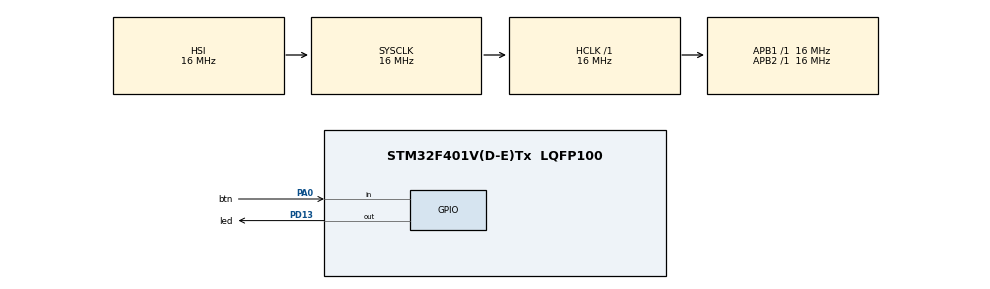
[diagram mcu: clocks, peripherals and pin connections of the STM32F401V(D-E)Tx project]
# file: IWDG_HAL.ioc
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IWDG.Prescaler=IWDG_PRESCALER_256
IWDG.Reload=625
Mcu.Family=STM32F4
Mcu.Name=STM32F401V(D-E)Tx
Mcu.Package=LQFP100
NVIC.PriorityGroup=NVIC_PRIORITYGROUP_4
PA0-WKUP.GPIO_Label=btn
PA0-WKUP.GPIO_PuPd=GPIO_PULLDOWN
PA0-WKUP.Signal=GPIO_Input
PD13.GPIO_Label=led
PD13.Signal=GPIO_Output
PH0\ -\ OSC_IN.Mode=HSE-External-Oscillator
PH0\ -\ OSC_IN.Signal=RCC_OSC_IN
PH1\ -\ OSC_OUT.Mode=HSE-External-Oscillator
PH1\ -\ OSC_OUT.Signal=RCC_OSC_OUT
ProjectManager.HeapSize=0x200
ProjectManager.StackSize=0x400
ProjectManager.TargetToolchain=STM32CubeIDE
RCC.AHBFreq_Value=16000000
RCC.APB1Freq_Value=16000000
RCC.APB2Freq_Value=16000000
RCC.CortexFreq_Value=16000000
RCC.HSE_VALUE=25000000
RCC.HSI_VALUE=16000000
RCC.LSE_VALUE=32768
RCC.SYSCLKFreq_VALUE=16000000
RCC.VCOOutputFreq_Value=192000000
VP_IWDG_VS_IWDG.Mode=IWDG_Activate
board=custom

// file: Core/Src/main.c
/* USER CODE BEGIN Header */
/**
  ******************************************************************************
  * @file           : main.c
  * @brief          : Investigate IWDG
  ******************************************************************************
  * @attention
  *
  * Copyright (c) 2022 STMicroelectronics.
  * All rights reserved.
  *
  * This software is licensed under terms that can be found in the LICENSE file
  * in the root directory of this software component.
  * If no LICENSE file comes with this software, it is provided AS-IS.
  *
  *							REVISION HISTORY
  *	Version 1.0: test reset MCU feature of IWDG.
  *
  ******************************************************************************
  */
/* USER CODE END Header */
#include "main.h"

/* USER CODE BEGIN PM */
#define btn_is_pressed 	(HAL_GPIO_ReadPin(btn_GPIO_Port, btn_Pin) == 1)
#define led_on 			HAL_GPIO_WritePin(led_GPIO_Port, led_Pin, 1)
/* USER CODE END PM */

IWDG_HandleTypeDef hiwdg;

void SystemClock_Config(void);
static void MX_GPIO_Init(void);
static void MX_IWDG_Init(void);

int main(void)
{

  /* MCU Configuration--------------------------------------------------------*/

  /* Reset of all peripherals, Initializes the Flash interface and the Systick. */
  HAL_Init();

  /* Configure the system clock */
  SystemClock_Config();

  /* Initialize all configured peripherals */
  MX_GPIO_Init();
  MX_IWDG_Init();

  /* Infinite loop */
  /* USER CODE BEGIN WHILE */
  while (1)
  {
	  if (btn_is_pressed)
		  led_on;
    /* USER CODE END WHILE */

  }
}

void SystemClock_Config(void)
{
  RCC_OscInitTypeDef RCC_OscInitStruct = {0};
  RCC_ClkInitTypeDef RCC_ClkInitStruct = {0};

  /** Configure the main internal regulator output voltage
  */
  __HAL_RCC_PWR_CLK_ENABLE();
  __HAL_PWR_VOLTAGESCALING_CONFIG(PWR_REGULATOR_VOLTAGE_SCALE2);

  /** Initializes the RCC Oscillators according to the specified parameters
  * in the RCC_OscInitTypeDef structure.
  */
  RCC_OscInitStruct.OscillatorType = RCC_OSCILLATORTYPE_HSI|RCC_OSCILLATORTYPE_LSI;
  RCC_OscInitStruct.HSIState = RCC_HSI_ON;
  RCC_OscInitStruct.HSICalibrationValue = RCC_HSICALIBRATION_DEFAULT;
  RCC_OscInitStruct.LSIState = RCC_LSI_ON;
  RCC_OscInitStruct.PLL.PLLState = RCC_PLL_NONE;
  if (HAL_RCC_OscConfig(&RCC_OscInitStruct) != HAL_OK)
  {
    Error_Handler();
  }

  /** Initializes the CPU, AHB and APB buses clocks
  */
  RCC_ClkInitStruct.ClockType = RCC_CLOCKTYPE_HCLK|RCC_CLOCKTYPE_SYSCLK
                              |RCC_CLOCKTYPE_PCLK1|RCC_CLOCKTYPE_PCLK2;
  RCC_ClkInitStruct.SYSCLKSource = RCC_SYSCLKSOURCE_HSI;
  RCC_ClkInitStruct.AHBCLKDivider = RCC_SYSCLK_DIV1;
  RCC_ClkInitStruct.APB1CLKDivider = RCC_HCLK_DIV1;
  RCC_ClkInitStruct.APB2CLKDivider = RCC_HCLK_DIV1;

  if (HAL_RCC_ClockConfig(&RCC_ClkInitStruct, FLASH_LATENCY_0) != HAL_OK)
  {
    Error_Handler();
  }
}

static void MX_IWDG_Init(void)
{

  hiwdg.Instance = IWDG;
  hiwdg.Init.Prescaler = IWDG_PRESCALER_256;
  hiwdg.Init.Reload = 625;
  if (HAL_IWDG_Init(&hiwdg) != HAL_OK)
  {
    Error_Handler();
  }

}

static void MX_GPIO_Init(void)
{
  GPIO_InitTypeDef GPIO_InitStruct = {0};

  /* GPIO Ports Clock Enable */
  __HAL_RCC_GPIOH_CLK_ENABLE();
  __HAL_RCC_GPIOA_CLK_ENABLE();
  __HAL_RCC_GPIOD_CLK_ENABLE();

  /*Configure GPIO pin Output Level */
  HAL_GPIO_WritePin(led_GPIO_Port, led_Pin, GPIO_PIN_RESET);

  /*Configure GPIO pin : btn_Pin */
  GPIO_InitStruct.Pin = btn_Pin;
  GPIO_InitStruct.Mode = GPIO_MODE_INPUT;
  GPIO_InitStruct.Pull = GPIO_PULLDOWN;
  HAL_GPIO_Init(btn_GPIO_Port, &GPIO_InitStruct);

  /*Configure GPIO pin : led_Pin */
  GPIO_InitStruct.Pin = led_Pin;
  GPIO_InitStruct.Mode = GPIO_MODE_OUTPUT_PP;
  GPIO_InitStruct.Pull = GPIO_NOPULL;
  GPIO_InitStruct.Speed = GPIO_SPEED_FREQ_LOW;
  HAL_GPIO_Init(led_GPIO_Port, &GPIO_InitStruct);

}

void Error_Handler(void)
{
  __disable_irq();
  while (1)
  {
  }
}
